# ADUCM350 register map
Vendor: Analog Devices; Series: ARMCM3; File version: 0.1
Cortex-M3 Microcontroller Device
CPU: CM3 r2p0, little endian, no MPU, no FPU, 3 interrupt priority bits
Registers are 16-bit, read-write, no defined reset value unless marked. A register's access mark holds for its fields unless they carry their own. Offsets are from the block's base; lines under a group give offsets from that group; [hi:lo] are bit positions; {n}, {i} and the like mark numbered series; 'fields as' and 'values as' point back to an identical list; <NAME> marks a mode.

## Memory map
0x40000000 ADI_T0 size 0x20 — Timer 0
0x40000400 ADI_T1 size 0x20 — Timer 1
0x40001000 ADI_PWM size 0x40 — Pulse Width Modulation
0x40002000 ADI_CLKCTL size 0x448 — Clock Control
0x40002400 ADI_PWRCTL size 0x80 — Power Management Unit
0x40002420 ADI_INTERRUPT size 0x18 — Interrupts
0x40002440 ADI_RESET size 0x4 — Reset
0x40002500 ADI_WUT size 0x44 — WakeUp Timer
0x40002580 ADI_WDT size 0x1C — Watchdog Timer
0x40002800 ADI_FEE size 0x84 — Flash Controller
0x40003000 ADI_I2C size 0x54 — I2C
0x40004000 ADI_SPI0 size 0x1C — Serial Peripheral Interface
0x40004400 ADI_SPI1 size 0x1C — Serial Peripheral Interface
0x40005000 ADI_UART size 0x34 — UART
0x40006000 ADI_GPIO0 size 0x28 — General Purpose Input Output
0x40006030 ADI_GPIO1 size 0x28 — General Purpose Input Output
0x40006060 ADI_GPIO2 size 0x28 — General Purpose Input Output
0x40008810 ADI_ANA size 0x78 — Analog Control
0x40010000 ADI_DMA size 0x1000 — Direct Memory Access
0x40020000 ADI_DAC size 0x5C — Digital To Analog Converter
0x40030000 ADI_ADC0 size 0x4C — Analog to Digital Converter
0x40030080 ADI_ADC1 size 0x60 — Analog to Digital Converter
0x400300E0 ADI_ADCSTEP size 0x10 — Analog to Digital Converter
0x400300F0 ADI_ADCDMA size 0xC — Analog to Digital Converter

## Interrupts
{n+1} EINT{n} (ADI_INTERRUPT) (n=0..7)
11 TIMER0 (ADI_T0)
12 TIMER1 (ADI_T1)
13 ADC0 (ADI_ADC0)
14 ADC1 (ADI_ADC1)
15 SINC2 (ADI_FEE)
16 FLASH (ADI_FEE)
18 SPI0 (ADI_SPI0)
19 SPI1 (ADI_SPI1)
20 I2CS (ADI_I2C)
21 I2CM (ADI_I2C)
22 DMA_ERR (ADI_DMA)
23 DMA_SPI1_TX (ADI_DMA)
24 DMA_SPI1_RX (ADI_DMA)
25 DMA_UART_TX (ADI_DMA)
26 DMA_UART_RX (ADI_DMA)
27 DMA_I2CS_TX (ADI_DMA)
28 DMA_I2CS_RX (ADI_DMA)
29 DMA_I2CM_TX (ADI_DMA)
30 DMA_I2CM_RX (ADI_DMA)
31 DMA_DAC (ADI_DMA)
32 DMA_ADC0 (ADI_DMA)
33 DMA_ADC1 (ADI_DMA)
34 DMA_SINC2 (ADI_DMA)
35 PWM_TRIP (ADI_PWM)
36 PWM_PAIR0 (ADI_PWM)
37 PWM_PAIR1 (ADI_PWM)
38 PWM_PAIR2 (ADI_PWM)

## ADI_T0 — Timer 0
Base 0x40000000
0x00 GPT0LD — 16-bit load value
  [15:0] VALUE — Load value
0x04 GPT0VAL — "16-bit timer value, read only."
  [15:0] VALUE — Current value
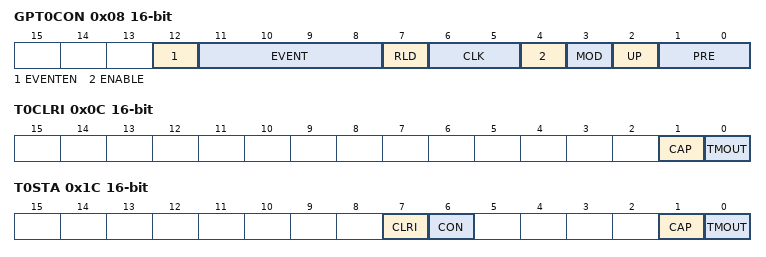
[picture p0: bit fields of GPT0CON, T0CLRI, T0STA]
0x08 GPT0CON — Control Register
  [12] EVENTEN — Enable time capture of an event
    0=DIS; 1=EN
  [11:8] EVENT — Event Select, selects 1 of the available events.
    0=T2 (- Wakeup Timer); {v}=EXT{v-1} (- External interrupt {v-1}) (v=1..8); 9=T3 (- Watchdog timer); 10=T1 (- Timer1); 11=ADC0; 12=ADC1; 13=STEP; 14=DMADONE; 15=FEE (- Flash controller)
  [7] RLD — Timer reload on write to clear register
    0=DIS; 1=EN
  [6:5] CLK — Clock Select
    0=UCLK (- System Clock); 1=PCLK (- Peripheral clock); 2=LFOSC (- Internal 32 kHz Oscillator); 3=LFXTAL (- External 32 kHz crystal)
  [4] ENABLE
    0=DIS; 1=EN
  [3] MOD — Mode
    0=FREERUN; 1=PERIODIC
  [2] UP — Count-up
    0=DIS; 1=EN
  [1:0] PRE — Prescaler
    0=DIV1; 1=DIV16; 2=DIV256; 3=DIV32768 (- If the selected clock source is UCLK then this setting results in a prescaler of 4.)
0x0C T0CLRI — Clear interrupt register
  [1] CAP — Clear captured event interrupt
    1=CLR
  [0] TMOUT — Clear timeout interrupt
    1=CLR
0x10 T0CAP — Capture Register
  [15:0] VALUE — Capture value
0x1C T0STA — Status Register
  [all] fields
    0=CLR; 1=SET
  [7] CLRI — Value updated in the timer clock domain
  [6] CON — Ready to receive commands
  [1] CAP — Capture event pending
  [0] TMOUT — Time out event occurred

## ADI_T1 — Timer 1
Base 0x40000400
0x00 T1LD — 16-bit load value
  [15:0] VALUE — Load value
0x04 T1VAL — "16-bit timer value, read only."
  [15:0] VALUE — Current value
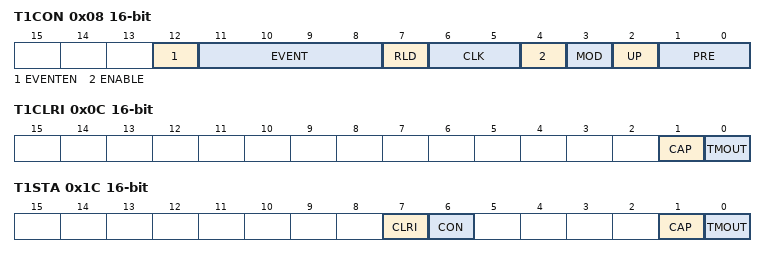
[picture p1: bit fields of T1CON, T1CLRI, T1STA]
0x08 T1CON — Control Register
  [12] EVENTEN — Enable time capture of an event
    0=DIS; 1=EN
  [11:8] EVENT — Event Select, selects 1 of the available events.
    0=COM; 1=T0 (- Timer0); 2=SPI0; 3=SPI1; 4=I2CS; 5=I2CM; 6=DMAERR; 7=DMADONE; 8=EXT1; 9=EXT2; 10=EXT3; 11=PWMTRIP; 12=PWM0; 13=PWM1; 14=PWM2; 15=ADC0
  [7] RLD — Timer reload on write to clear register
    0=DIS; 1=EN
  [6:5] CLK — Clock Select
    0=UCLK (- System Clock); 1=PCLK (- Peripheral clock); 2=LFOSC (- Internal 32 kHz Oscillator); 3=LFXTAL (- External 32 kHz crystal)
  [4] ENABLE
    0=DIS; 1=EN
  [3] MOD — Mode
    0=FREERUN; 1=PERIODIC
  [2] UP — Count-up
    0=DIS; 1=EN
  [1:0] PRE — Prescaler
    0=DIV1; 1=DIV16; 2=DIV256; 3=DIV32768 (- If the selected clock source is UCLK then this setting results in a prescaler of 4.)
0x0C T1CLRI — Clear interrupt register
  [1] CAP — Clear captured event interrupt
    1=CLR
  [0] TMOUT — Clear timeout interrupt
    1=CLR
0x10 T1CAP — Capture Register
  [15:0] VALUE — Capture value
0x1C T1STA — Status Register
  [all] fields
    0=CLR; 1=SET
  [7] CLRI — Value updated in the timer clock domain
  [6] CON — Ready to receive commands
  [1] CAP — Capture event pending
  [0] TMOUT — Time out event occurred
